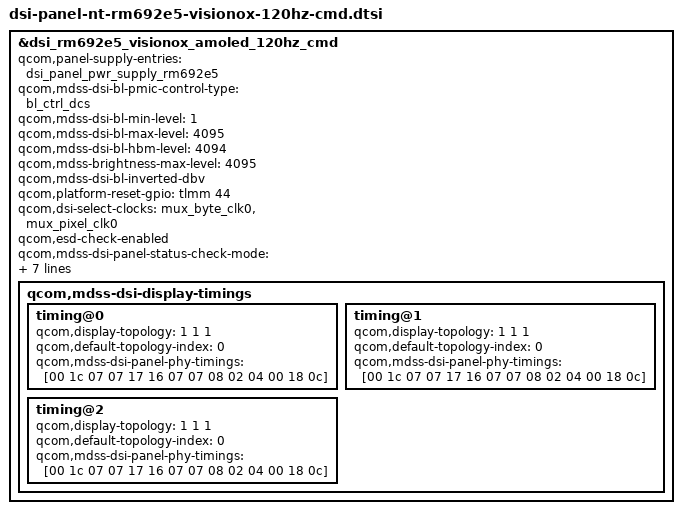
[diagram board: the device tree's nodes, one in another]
#include <dt-bindings/gpio/gpio.h>

&dsi_rm692e5_visionox_amoled_120hz_cmd {
	qcom,panel-supply-entries = <&dsi_panel_pwr_supply_rm692e5>;

	qcom,mdss-dsi-bl-pmic-control-type = "bl_ctrl_dcs";
	qcom,mdss-dsi-bl-min-level = <1>;
	qcom,mdss-dsi-bl-max-level = <4095>;
	qcom,mdss-dsi-bl-hbm-level = <4094>;
	qcom,mdss-brightness-max-level = <4095>;
	qcom,mdss-dsi-bl-inverted-dbv;

	qcom,platform-reset-gpio = <&tlmm 44 0>;
	qcom,dsi-select-clocks = "mux_byte_clk0", "mux_pixel_clk0";

	qcom,esd-check-enabled;
	qcom,mdss-dsi-panel-status-check-mode = "reg_read";
	qcom,mdss-dsi-panel-status-command = [06 01 00 01 00 00 01 0A];
	qcom,mdss-dsi-panel-status-command-state = "dsi_lp_mode";
	qcom,mdss-dsi-panel-status-value = <0x9c>;
	qcom,mdss-dsi-panel-status-read-length = <1>;

	qcom,mdss-dsi-display-timings {
		/* 120 Hz */
		timing@0 {
			qcom,display-topology = <1 1 1>;
			qcom,default-topology-index = <0>;
			qcom,mdss-dsi-panel-phy-timings = [00 1c 07 07 17 16 07 07 08 02 04 00 18 0c];
		};

		/* 90 Hz */
		timing@1 {
			qcom,display-topology = <1 1 1>;
			qcom,default-topology-index = <0>;
			qcom,mdss-dsi-panel-phy-timings = [00 1c 07 07 17 16 07 07 08 02 04 00 18 0c];
		};

		/* 60 Hz */
		timing@2 {
			qcom,display-topology = <1 1 1>;
			qcom,default-topology-index = <0>;
			qcom,mdss-dsi-panel-phy-timings = [00 1c 07 07 17 16 07 07 08 02 04 00 18 0c];
		};
	};
};
